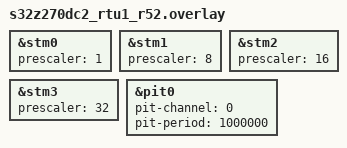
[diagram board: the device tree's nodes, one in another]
/*
 * Copyright 2022-2023 NXP
 *
 * SPDX-License-Identifier: Apache-2.0
 */

&stm0 {
	prescaler = <1>;
	status = "okay";
};

&stm1 {
	prescaler = <8>;
	status = "okay";
};

&stm2 {
	prescaler = <16>;
	status = "okay";
};

&stm3 {
	prescaler = <32>;
	status = "okay";
};

&pit0 {
	pit-channel = <0>;
	pit-period = <1000000>;
	status = "okay";
};
